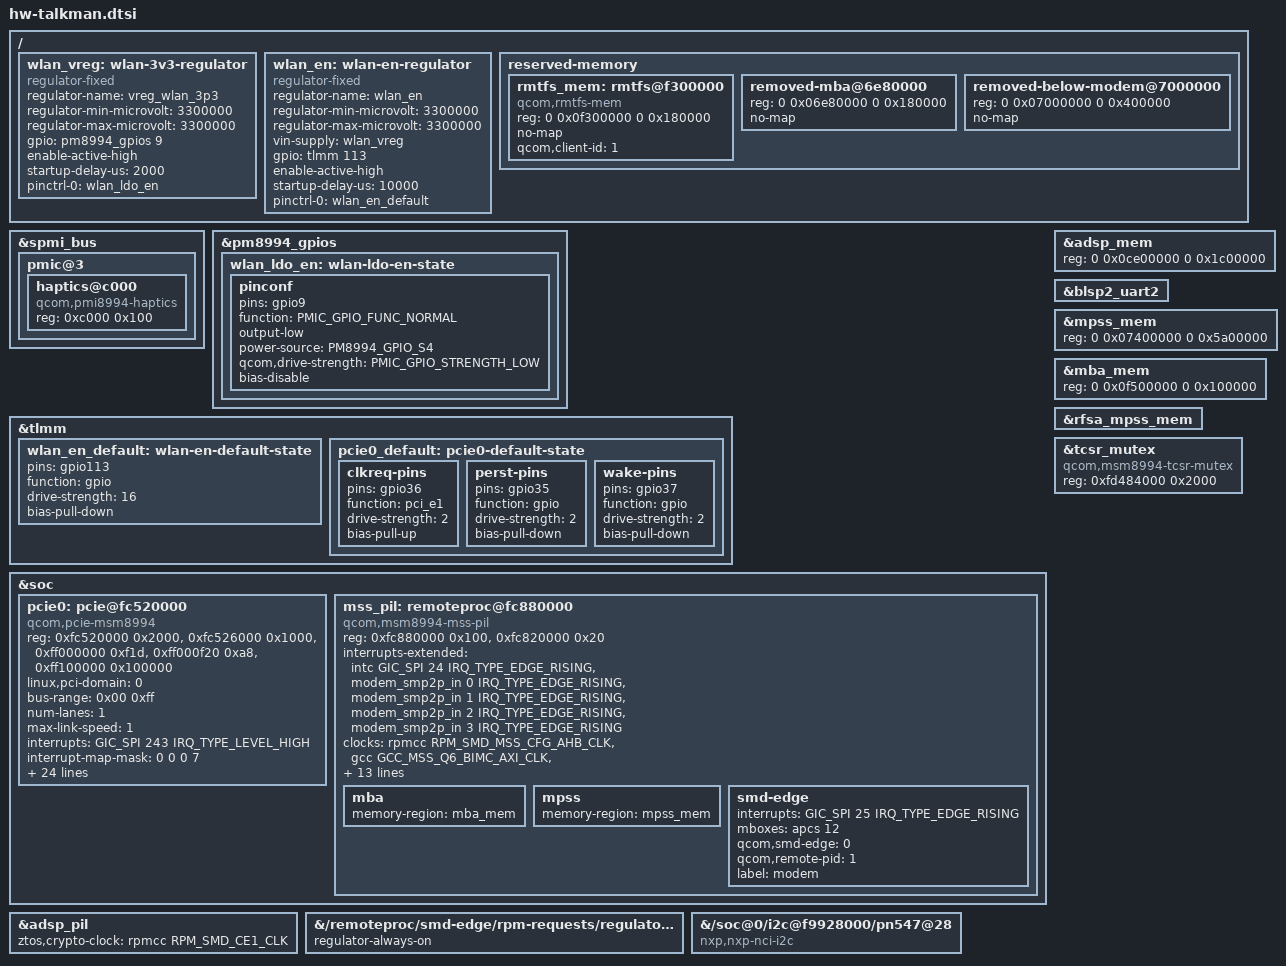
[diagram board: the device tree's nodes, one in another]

/*
 * The motor, and the Wi-Fi chip's PCIe bus and power. Values from the phone's downstream kernel:
 * its msm8992.dtsi (pcie0, cnss), and the talkman device tree for the motor. Holding Wi-Fi's strap
 * pins in cnss (GPIO 0, 1, 111, 112) high changed nothing when tried, so they are left alone.
 */
&spmi_bus {
	pmic@3 {
		haptics@c000 {
			compatible = "qcom,pmi8994-haptics";
			reg = <0xc000 0x100>;
		};
	};
};

&pm8994_gpios {
	wlan_ldo_en: wlan-ldo-en-state {
		pinconf {
			pins = "gpio9";
			function = PMIC_GPIO_FUNC_NORMAL;
			output-low;
			power-source = <PM8994_GPIO_S4>;
			qcom,drive-strength = <PMIC_GPIO_STRENGTH_LOW>;
			bias-disable;
		};
	};
};

&tlmm {
	wlan_en_default: wlan-en-default-state {
		pins = "gpio113";
		function = "gpio";
		drive-strength = <16>;
		bias-pull-down;
	};

	pcie0_default: pcie0-default-state {
		clkreq-pins {
			pins = "gpio36";
			function = "pci_e1";
			drive-strength = <2>;
			bias-pull-up;
		};
		perst-pins {
			pins = "gpio35";
			function = "gpio";
			drive-strength = <2>;
			bias-pull-down;
		};
		wake-pins {
			pins = "gpio37";
			function = "gpio";
			drive-strength = <2>;
			bias-pull-down;
		};
	};
};

/ {
	wlan_vreg: wlan-3v3-regulator {
		compatible = "regulator-fixed";
		regulator-name = "vreg_wlan_3p3";
		regulator-min-microvolt = <3300000>;
		regulator-max-microvolt = <3300000>;
		gpio = <&pm8994_gpios 9 GPIO_ACTIVE_HIGH>;
		enable-active-high;
		startup-delay-us = <2000>;
		pinctrl-names = "default";
		pinctrl-0 = <&wlan_ldo_en>;
	};

	wlan_en: wlan-en-regulator {
		compatible = "regulator-fixed";
		regulator-name = "wlan_en";
		regulator-min-microvolt = <3300000>;
		regulator-max-microvolt = <3300000>;
		vin-supply = <&wlan_vreg>;
		gpio = <&tlmm 113 GPIO_ACTIVE_HIGH>;
		enable-active-high;
		startup-delay-us = <10000>;
		pinctrl-names = "default";
		pinctrl-0 = <&wlan_en_default>;
	};
};

&soc {
	pcie0: pcie@fc520000 {
		compatible = "qcom,pcie-msm8994";
		reg = <0xfc520000 0x2000>,
		      <0xfc526000 0x1000>,
		      <0xff000000 0xf1d>,
		      <0xff000f20 0xa8>,
		      <0xff100000 0x100000>;
		reg-names = "parf", "phy", "dbi", "elbi", "config";
		device_type = "pci";
		linux,pci-domain = <0>;
		bus-range = <0x00 0xff>;
		num-lanes = <1>;
		max-link-speed = <1>;
		#address-cells = <3>;
		#size-cells = <2>;
		ranges = <0x01000000 0 0x00000000 0xff200000 0 0x00100000>,
			 <0x02000000 0 0xff300000 0xff300000 0 0x00d00000>;

		interrupts = <GIC_SPI 243 IRQ_TYPE_LEVEL_HIGH>;
		interrupt-names = "msi";
		#interrupt-cells = <1>;
		interrupt-map-mask = <0 0 0 7>;
		interrupt-map = <0 0 0 1 &intc GIC_SPI 244 IRQ_TYPE_LEVEL_HIGH>,
				<0 0 0 2 &intc GIC_SPI 245 IRQ_TYPE_LEVEL_HIGH>,
				<0 0 0 3 &intc GIC_SPI 247 IRQ_TYPE_LEVEL_HIGH>,
				<0 0 0 4 &intc GIC_SPI 248 IRQ_TYPE_LEVEL_HIGH>;

		clocks = <&gcc GCC_PCIE_0_AUX_CLK>,
			 <&gcc GCC_PCIE_0_CFG_AHB_CLK>,
			 <&gcc GCC_PCIE_0_MSTR_AXI_CLK>,
			 <&gcc GCC_PCIE_0_SLV_AXI_CLK>,
			 <&gcc PCIE_0_PHY_LDO>,
			 <&rpmcc RPM_SMD_LN_BB_CLK>,
			 <&gcc GCC_PCIE_0_PIPE_CLK>,
			 <&divclk4>;
		clock-names = "aux", "cfg", "bus_master", "bus_slave", "ldo", "ref", "pipe", "sleep";
		resets = <&gcc PCIE_0_CORE_RESET>, <&gcc PCIE_PHY_0_RESET>;
		reset-names = "core", "phy";
		power-domains = <&gcc PCIE_0_GDSC>;

		vdda-supply = <&vreg_l28a_1p0>;
		vddp-supply = <&vreg_l12a_1p8>;
		vdd-wlan-io-supply = <&vreg_s4a_1p8>;
		vdd-wlan-xtal-supply = <&vreg_l30a_1p8>;
		vddpe-3v3-supply = <&wlan_en>;

		perst-gpios = <&tlmm 35 GPIO_ACTIVE_LOW>;
		pinctrl-names = "default";
		pinctrl-0 = <&pcie0_default>;
	};
};

/*
 * The secure firmware checks a DSP's image with the crypto engine, whose clock has to be on: the
 * downstream kernel's "scm_ce1_clk". Without it the DSP is refused (-22). A property the kernel's
 * dependency scan does not read: under "clocks" the driver order changes and the power controller
 * stops answering on most boots, and on the scm device the phone does not boot at all. The loader
 * takes it as the DSP starts (patch-hw.py).
 */
&adsp_pil {
	ztos,crypto-clock = <&rpmcc RPM_SMD_CE1_CLK>;
};

/*
 * The audio DSP's memory, as the phone's own downstream device tree has it. At the 0x0ca00000 of
 * the tree here, writing the firmware there restarts the phone, with no record of why.
 * It overlaps venus_mem's place, which nothing here uses.
 */
&adsp_mem {
	reg = <0 0x0ce00000 0 0x1c00000>;
};

/ {
	reserved-memory {
		/*
		 * The modem's copy of its file systems in memory, and its boot image. The downstream
		 * kernel takes both from ordinary memory, wherever it has some.
		 */
		rmtfs_mem: rmtfs@f300000 {
			compatible = "qcom,rmtfs-mem";
			reg = <0 0x0f300000 0 0x180000>;
			no-map;
			qcom,client-id = <1>;
		};

		/*
		 * Off limits. The tree's place for the boot image is in the phone's own "removed"
		 * range, 0x5000000 to 0x7200000: writing there restarts the phone. Then what moving
		 * the modem leaves below it.
		 */
		removed-mba@6e80000 {
			reg = <0 0x06e80000 0 0x180000>;
			no-map;
		};

		removed-below-modem@7000000 {
			reg = <0 0x07000000 0 0x400000>;
			no-map;
		};
	};
};

/*
 * Bluetooth's UART by its FIFO. By DMA the bytes count as sent and the chip never answers:
 * "command 0xfc00 tx timeout".
 */
&blsp2_uart2 {
	/delete-property/ dmas;
	/delete-property/ dma-names;
};

/*
 * The modem, at the addresses in the phone's own downstream device tree: its memory ends where the
 * audio DSP's begins. Its driver stays stopped until something starts it.
 */
&mpss_mem {
	reg = <0 0x07400000 0 0x5a00000>;
};

&mba_mem {
	reg = <0 0x0f500000 0 0x100000>;
};

&rfsa_mpss_mem {
	/delete-property/ compatible;
	/delete-property/ qcom,client-id;
};

&tcsr_mutex {
	compatible = "qcom,msm8994-tcsr-mutex", "qcom,tcsr-mutex", "syscon";
	reg = <0xfd484000 0x2000>;
};

&soc {
	mss_pil: remoteproc@fc880000 {
		compatible = "qcom,msm8994-mss-pil";
		reg = <0xfc880000 0x100>, <0xfc820000 0x20>;
		reg-names = "qdsp6", "rmb";

		interrupts-extended = <&intc GIC_SPI 24 IRQ_TYPE_EDGE_RISING>,
				      <&modem_smp2p_in 0 IRQ_TYPE_EDGE_RISING>,
				      <&modem_smp2p_in 1 IRQ_TYPE_EDGE_RISING>,
				      <&modem_smp2p_in 2 IRQ_TYPE_EDGE_RISING>,
				      <&modem_smp2p_in 3 IRQ_TYPE_EDGE_RISING>;
		interrupt-names = "wdog", "fatal", "ready", "handover", "stop-ack";

		clocks = <&rpmcc RPM_SMD_MSS_CFG_AHB_CLK>,
			 <&gcc GCC_MSS_Q6_BIMC_AXI_CLK>,
			 <&gcc GCC_BOOT_ROM_AHB_CLK>,
			 <&gcc GPLL0_OUT_MSSCC>,
			 <&xo_board>;
		clock-names = "iface", "bus", "mem", "gpll0_mss", "xo";

		resets = <&gcc MSS_RESET>;
		reset-names = "mss_restart";

		qcom,halt-regs = <&tcsr_mutex 0x1180 0x1200 0x1280>;

		qcom,smem-states = <&modem_smp2p_out 0>;
		qcom,smem-state-names = "stop";

		power-domains = <&rpmpd MSM8994_VDDCX>, <&rpmpd MSM8994_VDDMX>;
		power-domain-names = "cx", "mx";

		pll-supply = <&vreg_l12a_1p8>;
		mss-supply = <&vreg_s7a_1p0>;

		firmware-name = "qcdsp1v28992.mbn", "qcdsp28992.mbn";

		mba {
			memory-region = <&mba_mem>;
		};

		mpss {
			memory-region = <&mpss_mem>;
		};

		smd-edge {
			interrupts = <GIC_SPI 25 IRQ_TYPE_EDGE_RISING>;
			mboxes = <&apcs 12>;
			qcom,smd-edge = <0>;
			qcom,remote-pid = <1>;
			label = "modem";
		};
	};
};

/*
 * NFC. The chip answers NCI, not the PN544 protocol the tree's node asks for. Its supply is L9, which
 * the modem otherwise switches with its radio, and it only wakes with L9 already up.
 */
&{/remoteproc/smd-edge/rpm-requests/regulators-0/l9} {
	regulator-always-on;
};

&{/soc@0/i2c@f9928000/pn547@28} {
	compatible = "nxp,nxp-nci-i2c";
};
